# nrf54lv10a_enga_application register map
Vendor: Nordic Semiconductor; Series: nrf54l; File version: 1
CPU: CM33 r0p4, little endian, MPU, FPU, 3 interrupt priority bits, 270 interrupts, 4 SAU regions
Registers are 32-bit, read-write, reset 0x0 unless marked. A register's access mark holds for its fields unless they carry their own. Offsets are from the block's base; [hi:lo] are bit positions; lines under a group give offsets from that group; {n}, {i} and the like mark numbered series; 'fields as' and 'values as' point back to an identical list.

## GLOBAL_PULSEDET00_S — PULSEDET peripheral 0
Base 0x5007A000
Same registers: GLOBAL_PULSEDET01_S 0x5007B000, GLOBAL_PULSEDET10_S 0x500A0000, GLOBAL_PULSEDET20_S 0x500EC000, GLOBAL_PULSEDET30_S 0x50110000
0x00 TASKS_RESET wo — Reset PULSEDET analog macros
  [0] TASKS_RESET
    1=Trigger task
0x400 STATUSANA ro — Status register for analog macro cells (32*n) to 32*(n+1)-1. Status registers offsets :0x400+0x4*n, n = 1:64
0x500 ENABLE — Enable tamper event and automatic reset.
  [0] ENABLE
0x504 MASK reset 0xFF — Mask PULSEDET analog macros
  [7:0] MASK

## GLOBAL_VREGRLDO_S — VREGRLDO peripheral
Base 0x5007C000
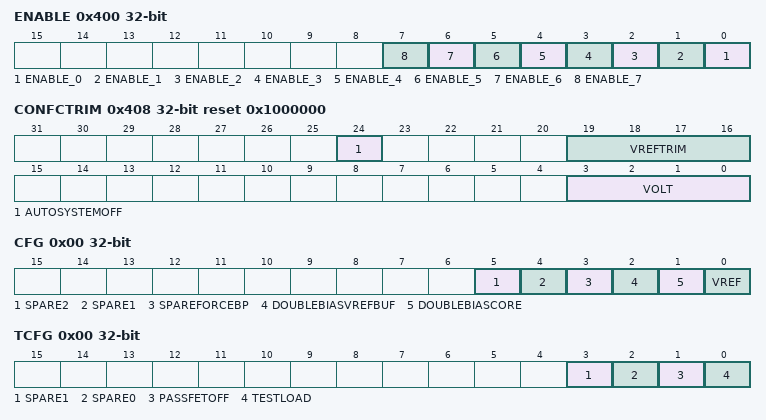
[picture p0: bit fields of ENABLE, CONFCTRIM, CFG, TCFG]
0x400 ENABLE — Enable VREGRLDO and use it for selected RAM blocks
  [all] fields
    0=Disabled; 1=Enabled
  [n] ENABLE_{n} (n=0..7) — Enable VREGLDO and use it for RAM block {n}
0x404 STATUS ro — VREGRLDO status
  [0] READY — VREGLDO ready
    0=Not ready for operation; 1=Ready and operating
0x408 CONFCTRIM reset 0x1000000 — Combined configuration and trim register
  [24] AUTOSYSTEMOFF — Enable automatic disabling of the regulator when in System Off with no RAM retained
    0=Manual (Regulator is not automatically disabled in System OFF); 1=Automatic (Regulator is automatically disabled in System OFF mode with no RAM retained)
  [19:16] VREFTRIM — Output voltage trim register
  [3:0] VOLT — Select/configureLDO output voltage
    0=0V5 (0.5 V); 8=0V58 (0.58 V); 15=0V65 (0.65 V)
0x500 OVERRIDE group — Unspecified
  0x00 CFG — CFG override configuration
    [5] SPARE2
    [4] SPARE1
    [3] SPAREFORCEBP
      0=Disabled; 1=Enabled
    [2] DOUBLEBIASVREFBUF
      0=Disabled; 1=Enabled
    [1] DOUBLEBIASCORE
      0=Disabled; 1=Enabled
    [0] VREF — Switch VREF generation from VREF_ULP to proportional of VDD_0V9
      0=VrefUlp; 1=Vdd0V9
0x600 DFT group — Unspecified
  0x00 TCFG — Test configuration
    [3] SPARE1
    [2] SPARE0
    [1] PASSFETOFF
      0=NoForceOff (Do not force passfet off); 1=ForceOff (Force passfet off)
    [0] TESTLOAD
      0=Off (Test load off); 1=On (Test load on)
  0x04 ATB0CONFIG — ATB configuration
    [2:0] ATB0CFG
      0=HiZ (Allow other IPs to use ATB0); 4=UnbufferedVLdo (Unbuffered LDO internal output to ATB0); 5=BufferedVldo (Buffered LDO internal output to ATB0); 6=VddRldo0 (Buffered LDO output 0, ie VM0 from VM_FB, to ATB0); 7=Vref (Connect buffered VREF to ATB0)
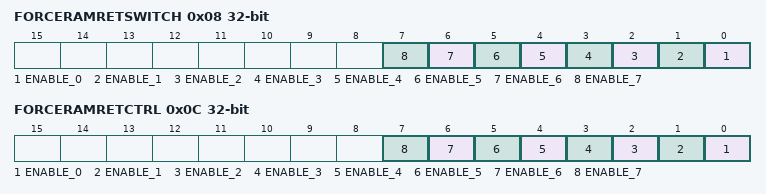
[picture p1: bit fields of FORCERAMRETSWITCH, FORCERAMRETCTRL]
  0x08 FORCERAMRETSWITCH — Force RAM retention switches
    [all] fields
      0=Disabled (Do not force (default behavior)); 1=Enabled (Force RAM retention)
    [n] ENABLE_{n} (n=0..7) — Force RAM retention switches on RAM block {n}
  0x0C FORCERAMRETCTRL — Force RAM retention control signal
    [all] fields
      0=Disabled (Do not force (default behavior)); 1=Enabled (Force)
    [n] ENABLE_{n} (n=0..7) — Force RAM retention control signal for RAM block {n}

## GLOBAL_ECCRAMC_S — ECCRAMC peripheral
Base 0x5007D000
0x00 TASKS_CLEAR wo — Clear ECC SECCOUNT and DEDCOUNT registers
  [0] TASKS_CLEAR
    1=Trigger task
0x100 EVENTS_SEC — SEC event occurred
  [0] EVENTS_SEC
    0=NotGenerated (Event not generated); 1=Generated (Event generated)
0x104 EVENTS_DED — DED event occurred
  [0] EVENTS_DED
    values as EVENTS_SEC.EVENTS_SEC
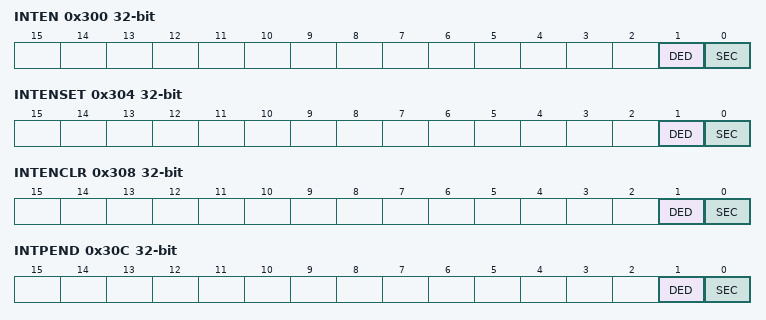
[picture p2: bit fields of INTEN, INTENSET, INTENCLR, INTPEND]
0x300 INTEN — Enable or disable interrupt
  [1] DED — Enable or disable interrupt for event DED
    0=Disabled; 1=Enabled
  [0] SEC — Enable or disable interrupt for event SEC
    0=Disabled; 1=Enabled
0x304 INTENSET — Enable interrupt
  [1] DED — Write '1' to enable interrupt for event DED
    on read: 0=Disabled (Read: Disabled); 1=Enabled (Read: Enabled) | on write: 1=Set (Enable)
  [0] SEC — Write '1' to enable interrupt for event SEC
    values as DED
0x308 INTENCLR — Disable interrupt
  [1] DED — Write '1' to disable interrupt for event DED
    on read: 0=Disabled (Read: Disabled); 1=Enabled (Read: Enabled) | on write: 1=Clear (Disable)
  [0] SEC — Write '1' to disable interrupt for event SEC
    values as DED
0x30C INTPEND ro — Pending interrupts
  [1] DED — Read pending status of interrupt for event DED
    on read: 0=NotPending (Read: Not pending); 1=Pending (Read: Pending)
  [0] SEC — Read pending status of interrupt for event SEC
    values as DED
0x400 ECCDIS — Disable ECC for RAM
  [0] DISABLED — ECC is disabled
    0=Enabled; 1=Disabled
0x404 ECCMON group — ECC monitoring registers
  0x00 ENABLE — Enable monitoring counters
    [0] ENABLED — ECC monitoring counters are enabled
      1=Enabled; 0=Disabled
  0x04 SECCOUNT ro — Number of single-bit errors corrected
    [15:0] COUNT — Counter value
  0x08 DEDCOUNT ro — Number of non-correctable bit errors
    [15:0] COUNT — Counter value
  0x0C ECCPARITY ro — ECC parity bits
    [31:0] PARITY — Parity bits value

## Notices in the file
Copyright (c) 2010 - 2025, Nordic Semiconductor ASA
All rights reserved.
Redistribution and use in source and binary forms, with or without modification,
are permitted provided that the following conditions are met:
1. Redistributions of source code must retain the above copyright notice, this
list of conditions and the following disclaimer.
2. Redistributions in binary form, except as embedded into a Nordic
Semiconductor ASA integrated circuit in a product or a software update for
such product, must reproduce the above copyright notice, this list of
conditions and the following disclaimer in the documentation and/or other
materials provided with the distribution.
3. Neither the name of Nordic Semiconductor ASA nor the names of its
contributors may be used to endorse or promote products derived from this
software without specific prior written permission.
4. This software, with or without modification, must only be used with a
Nordic Semiconductor ASA integrated circuit.
5. Any software provided in binary form under this license must not be reverse
engineered, decompiled, modified and/or disassembled.
THIS SOFTWARE IS PROVIDED BY NORDIC SEMICONDUCTOR ASA "AS IS" AND ANY EXPRESS
OR IMPLIED WARRANTIES, INCLUDING, BUT NOT LIMITED TO, THE IMPLIED WARRANTIES
OF MERCHANTABILITY, NONINFRINGEMENT, AND FITNESS FOR A PARTICULAR PURPOSE ARE
DISCLAIMED. IN NO EVENT SHALL NORDIC SEMICONDUCTOR ASA OR CONTRIBUTORS BE
LIABLE FOR ANY DIRECT, INDIRECT, INCIDENTAL, SPECIAL, EXEMPLARY, OR
CONSEQUENTIAL DAMAGES (INCLUDING, BUT NOT LIMITED TO, PROCUREMENT OF SUBSTITUTE
GOODS OR SERVICES; LOSS OF USE, DATA, OR PROFITS; OR BUSINESS INTERRUPTION)
HOWEVER CAUSED AND ON ANY THEORY OF LIABILITY, WHETHER IN CONTRACT, STRICT
LIABILITY, OR TORT (INCLUDING NEGLIGENCE OR OTHERWISE) ARISING IN ANY WAY OUT
OF THE USE OF THIS SOFTWARE, EVEN IF ADVISED OF THE POSSIBILITY OF SUCH DAMAGE.
